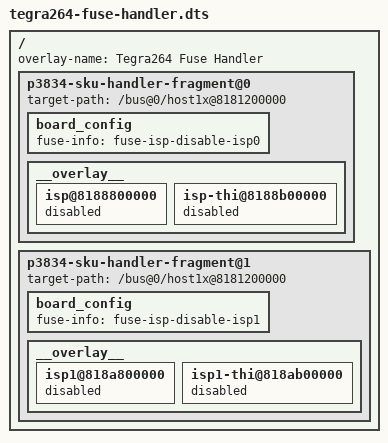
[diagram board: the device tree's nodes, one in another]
// SPDX-License-Identifier: GPL-2.0-only
// SPDX-FileCopyrightText: Copyright (c) 2025 NVIDIA CORPORATION & AFFILIATES.  All rights reserved.

/dts-v1/;
/plugin/;

/ {
        overlay-name = "Tegra264 Fuse Handler";

	p3834-sku-handler-fragment@0 {
		target-path = "/bus@0/host1x@8181200000";
		board_config {
			fuse-info = "fuse-isp-disable-isp0";
		};
		__overlay__ {
			isp@8188800000 {
				status = "disabled";
			};

			isp-thi@8188b00000 {
				status = "disabled";
			};
		};
	};

	p3834-sku-handler-fragment@1 {
		target-path = "/bus@0/host1x@8181200000";
		board_config {
			fuse-info = "fuse-isp-disable-isp1";
		};
		__overlay__ {
			isp1@818a800000 {
				status = "disabled";
			};

			isp1-thi@818ab00000 {
				status = "disabled";
			};
		};
	};
};
